# cslr_aif register map
Vendor: Texas Instruments
Registers are 32-bit, access per field, reset 0x0 unless marked. A register's access mark holds for its fields unless they carry their own. Offsets are as the file gives them; [hi:lo] are bit positions; {n}, {i} and the like mark numbered series; 'fields as' and 'values as' point back to an identical list.

## AIF (part 4 of 5) — High-speed interface for BTS antenna data
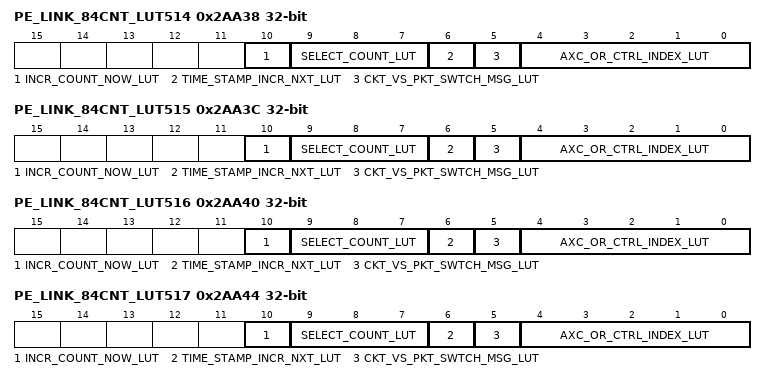
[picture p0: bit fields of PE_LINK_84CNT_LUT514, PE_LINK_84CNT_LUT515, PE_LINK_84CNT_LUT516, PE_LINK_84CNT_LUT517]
0x2AA38 PE_LINK_84CNT_LUT514 — Protocol Encoder Link 84 Count LUT{PE_LINK_84CNT_LUT5}
  [10] INCR_COUNT_NOW_LUT rw — controls counter to increment, Incremented value is used for next operation (current operation uses current counter value)
    1=ICNR; 0=NO_INCR
  [9:7] SELECT_COUNT_LUT rw — Bits [2:0]: "0"-"3": Selects 4x Control Slot Counters or "4": 1x Data Slot Counter for Increment and for use with transmission rule
    {v}=CTRL{v} (v=0..3); 4=DATA
  [6] TIME_STAMP_INCR_NXT_LUT rw — Controls Time Stamp to increment, Incremented value is used for next message
  [5] CKT_VS_PKT_SWTCH_MSG_LUT rw — 0: circuit switched data
    0=PACKET; 1=CIRCUIT
  [4:0] AXC_OR_CTRL_INDEX_LUT rw — Bits [4:0]: Index for accessing the identity LUT.
0x2AA3C PE_LINK_84CNT_LUT515 — Protocol Encoder Link 84 Count LUT{PE_LINK_84CNT_LUT5}
  fields as PE_LINK_84CNT_LUT514
0x2AA40 PE_LINK_84CNT_LUT516 — Protocol Encoder Link 84 Count LUT{PE_LINK_84CNT_LUT5}
  fields as PE_LINK_84CNT_LUT514
0x2AA44 PE_LINK_84CNT_LUT517 — Protocol Encoder Link 84 Count LUT{PE_LINK_84CNT_LUT5}
  fields as PE_LINK_84CNT_LUT514
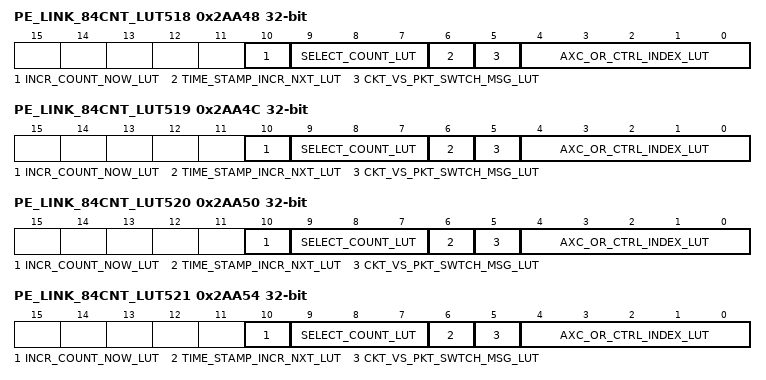
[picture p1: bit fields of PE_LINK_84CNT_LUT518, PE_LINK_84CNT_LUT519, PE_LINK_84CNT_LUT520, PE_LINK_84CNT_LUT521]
0x2AA48 PE_LINK_84CNT_LUT518 — Protocol Encoder Link 84 Count LUT{PE_LINK_84CNT_LUT5}
  fields as PE_LINK_84CNT_LUT514
0x2AA4C PE_LINK_84CNT_LUT519 — Protocol Encoder Link 84 Count LUT{PE_LINK_84CNT_LUT5}
  fields as PE_LINK_84CNT_LUT514
0x2AA50 PE_LINK_84CNT_LUT520 — Protocol Encoder Link 84 Count LUT{PE_LINK_84CNT_LUT5}
  fields as PE_LINK_84CNT_LUT514
0x2AA54 PE_LINK_84CNT_LUT521 — Protocol Encoder Link 84 Count LUT{PE_LINK_84CNT_LUT5}
  fields as PE_LINK_84CNT_LUT514
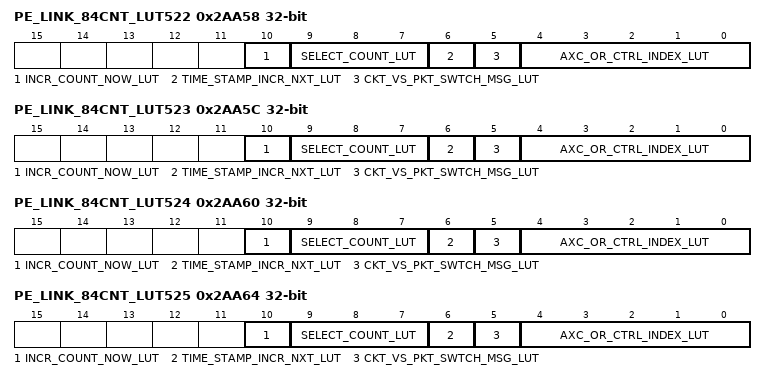
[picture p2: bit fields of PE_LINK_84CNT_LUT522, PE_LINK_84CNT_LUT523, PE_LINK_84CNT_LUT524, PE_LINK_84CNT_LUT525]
0x2AA58 PE_LINK_84CNT_LUT522 — Protocol Encoder Link 84 Count LUT{PE_LINK_84CNT_LUT5}
  fields as PE_LINK_84CNT_LUT514
0x2AA5C PE_LINK_84CNT_LUT523 — Protocol Encoder Link 84 Count LUT{PE_LINK_84CNT_LUT5}
  fields as PE_LINK_84CNT_LUT514
0x2AA60 PE_LINK_84CNT_LUT524 — Protocol Encoder Link 84 Count LUT{PE_LINK_84CNT_LUT5}
  fields as PE_LINK_84CNT_LUT514
0x2AA64 PE_LINK_84CNT_LUT525 — Protocol Encoder Link 84 Count LUT{PE_LINK_84CNT_LUT5}
  fields as PE_LINK_84CNT_LUT514
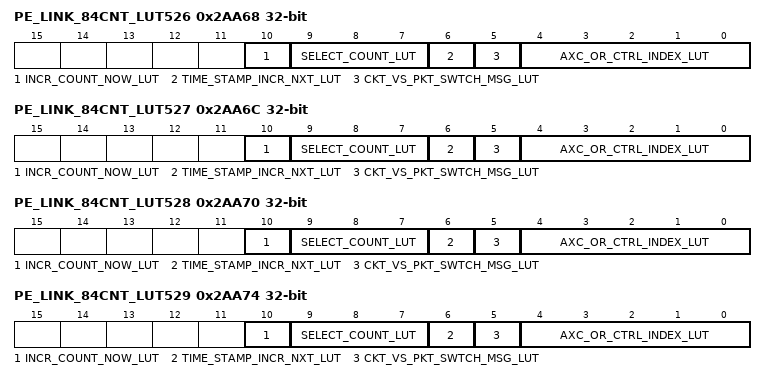
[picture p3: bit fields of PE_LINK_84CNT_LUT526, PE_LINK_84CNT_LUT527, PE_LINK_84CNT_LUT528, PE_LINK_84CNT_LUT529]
0x2AA68 PE_LINK_84CNT_LUT526 — Protocol Encoder Link 84 Count LUT{PE_LINK_84CNT_LUT5}
  fields as PE_LINK_84CNT_LUT514
0x2AA6C PE_LINK_84CNT_LUT527 — Protocol Encoder Link 84 Count LUT{PE_LINK_84CNT_LUT5}
  fields as PE_LINK_84CNT_LUT514
0x2AA70 PE_LINK_84CNT_LUT528 — Protocol Encoder Link 84 Count LUT{PE_LINK_84CNT_LUT5}
  fields as PE_LINK_84CNT_LUT514
0x2AA74 PE_LINK_84CNT_LUT529 — Protocol Encoder Link 84 Count LUT{PE_LINK_84CNT_LUT5}
  fields as PE_LINK_84CNT_LUT514
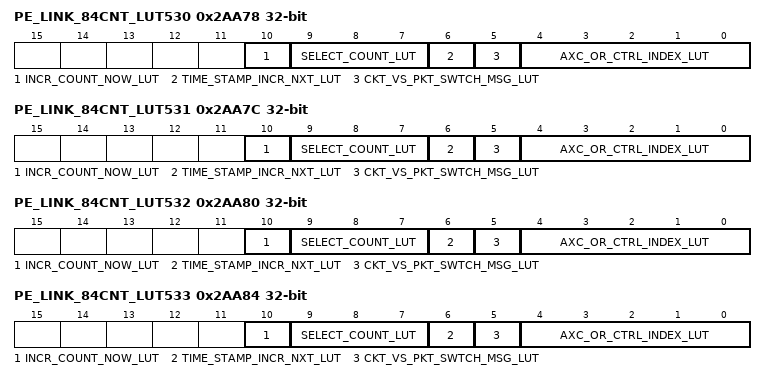
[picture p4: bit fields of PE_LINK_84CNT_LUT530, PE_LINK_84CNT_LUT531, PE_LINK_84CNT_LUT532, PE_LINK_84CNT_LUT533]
0x2AA78 PE_LINK_84CNT_LUT530 — Protocol Encoder Link 84 Count LUT{PE_LINK_84CNT_LUT5}
  fields as PE_LINK_84CNT_LUT514
0x2AA7C PE_LINK_84CNT_LUT531 — Protocol Encoder Link 84 Count LUT{PE_LINK_84CNT_LUT5}
  fields as PE_LINK_84CNT_LUT514
0x2AA80 PE_LINK_84CNT_LUT532 — Protocol Encoder Link 84 Count LUT{PE_LINK_84CNT_LUT5}
  fields as PE_LINK_84CNT_LUT514
0x2AA84 PE_LINK_84CNT_LUT533 — Protocol Encoder Link 84 Count LUT{PE_LINK_84CNT_LUT5}
  fields as PE_LINK_84CNT_LUT514
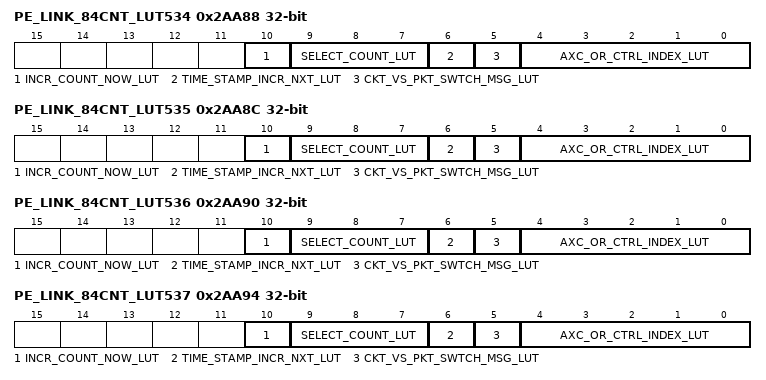
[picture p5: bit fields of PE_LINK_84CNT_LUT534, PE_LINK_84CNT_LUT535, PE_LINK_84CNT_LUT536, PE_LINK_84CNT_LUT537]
0x2AA88 PE_LINK_84CNT_LUT534 — Protocol Encoder Link 84 Count LUT{PE_LINK_84CNT_LUT5}
  fields as PE_LINK_84CNT_LUT514
0x2AA8C PE_LINK_84CNT_LUT535 — Protocol Encoder Link 84 Count LUT{PE_LINK_84CNT_LUT5}
  fields as PE_LINK_84CNT_LUT514
0x2AA90 PE_LINK_84CNT_LUT536 — Protocol Encoder Link 84 Count LUT{PE_LINK_84CNT_LUT5}
  fields as PE_LINK_84CNT_LUT514
0x2AA94 PE_LINK_84CNT_LUT537 — Protocol Encoder Link 84 Count LUT{PE_LINK_84CNT_LUT5}
  fields as PE_LINK_84CNT_LUT514
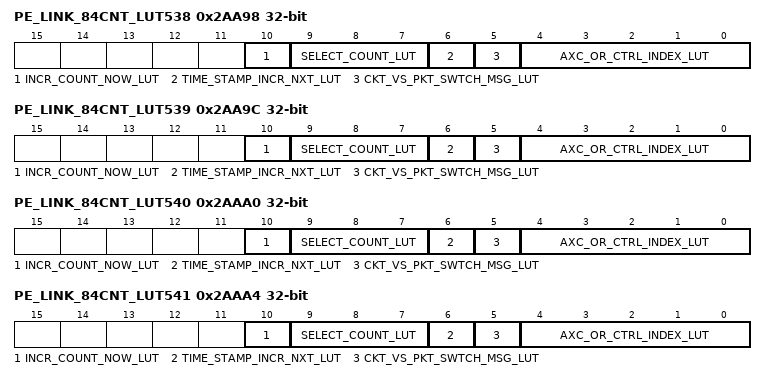
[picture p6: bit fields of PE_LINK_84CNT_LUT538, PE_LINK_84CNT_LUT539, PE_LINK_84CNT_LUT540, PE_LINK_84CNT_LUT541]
0x2AA98 PE_LINK_84CNT_LUT538 — Protocol Encoder Link 84 Count LUT{PE_LINK_84CNT_LUT5}
  fields as PE_LINK_84CNT_LUT514
0x2AA9C PE_LINK_84CNT_LUT539 — Protocol Encoder Link 84 Count LUT{PE_LINK_84CNT_LUT5}
  fields as PE_LINK_84CNT_LUT514
0x2AAA0 PE_LINK_84CNT_LUT540 — Protocol Encoder Link 84 Count LUT{PE_LINK_84CNT_LUT5}
  fields as PE_LINK_84CNT_LUT514
0x2AAA4 PE_LINK_84CNT_LUT541 — Protocol Encoder Link 84 Count LUT{PE_LINK_84CNT_LUT5}
  fields as PE_LINK_84CNT_LUT514
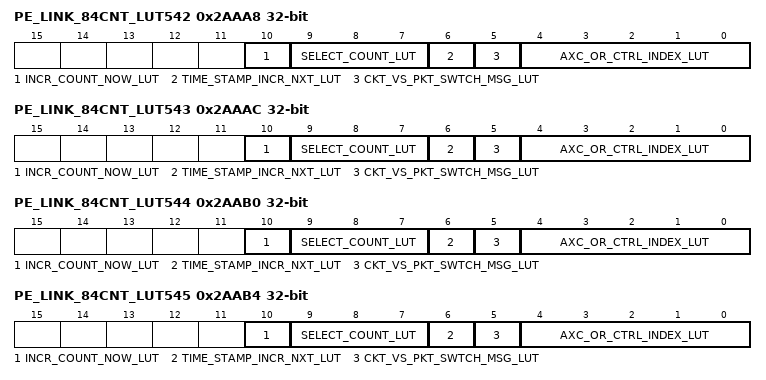
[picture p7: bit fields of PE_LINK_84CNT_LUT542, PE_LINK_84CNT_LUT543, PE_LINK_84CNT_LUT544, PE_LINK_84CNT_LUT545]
0x2AAA8 PE_LINK_84CNT_LUT542 — Protocol Encoder Link 84 Count LUT{PE_LINK_84CNT_LUT5}
  fields as PE_LINK_84CNT_LUT514
0x2AAAC PE_LINK_84CNT_LUT543 — Protocol Encoder Link 84 Count LUT{PE_LINK_84CNT_LUT5}
  fields as PE_LINK_84CNT_LUT514
0x2AAB0 PE_LINK_84CNT_LUT544 — Protocol Encoder Link 84 Count LUT{PE_LINK_84CNT_LUT5}
  fields as PE_LINK_84CNT_LUT514
0x2AAB4 PE_LINK_84CNT_LUT545 — Protocol Encoder Link 84 Count LUT{PE_LINK_84CNT_LUT5}
  fields as PE_LINK_84CNT_LUT514
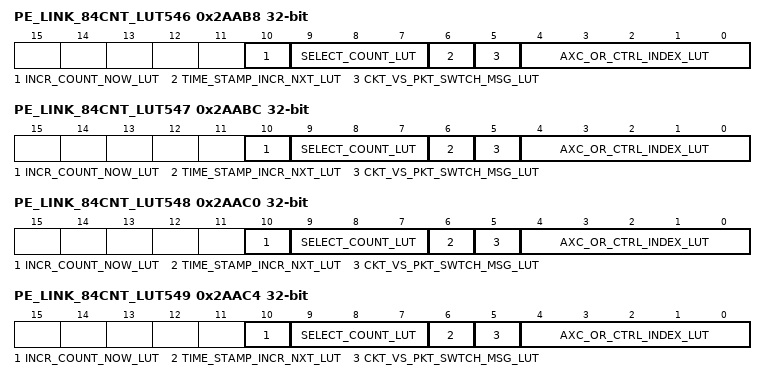
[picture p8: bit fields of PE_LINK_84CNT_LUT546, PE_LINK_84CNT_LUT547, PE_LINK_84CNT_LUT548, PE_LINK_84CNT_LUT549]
0x2AAB8 PE_LINK_84CNT_LUT546 — Protocol Encoder Link 84 Count LUT{PE_LINK_84CNT_LUT5}
  fields as PE_LINK_84CNT_LUT514
0x2AABC PE_LINK_84CNT_LUT547 — Protocol Encoder Link 84 Count LUT{PE_LINK_84CNT_LUT5}
  fields as PE_LINK_84CNT_LUT514
0x2AAC0 PE_LINK_84CNT_LUT548 — Protocol Encoder Link 84 Count LUT{PE_LINK_84CNT_LUT5}
  fields as PE_LINK_84CNT_LUT514
0x2AAC4 PE_LINK_84CNT_LUT549 — Protocol Encoder Link 84 Count LUT{PE_LINK_84CNT_LUT5}
  fields as PE_LINK_84CNT_LUT514
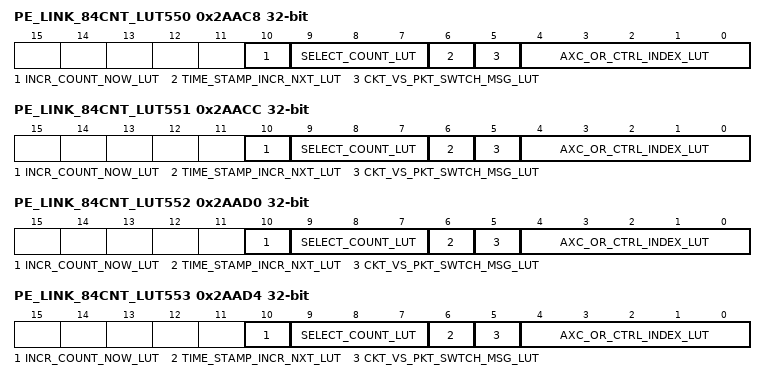
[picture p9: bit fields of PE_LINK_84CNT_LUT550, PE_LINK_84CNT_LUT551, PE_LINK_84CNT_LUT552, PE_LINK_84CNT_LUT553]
0x2AAC8 PE_LINK_84CNT_LUT550 — Protocol Encoder Link 84 Count LUT{PE_LINK_84CNT_LUT5}
  fields as PE_LINK_84CNT_LUT514
0x2AACC PE_LINK_84CNT_LUT551 — Protocol Encoder Link 84 Count LUT{PE_LINK_84CNT_LUT5}
  fields as PE_LINK_84CNT_LUT514
0x2AAD0 PE_LINK_84CNT_LUT552 — Protocol Encoder Link 84 Count LUT{PE_LINK_84CNT_LUT5}
  fields as PE_LINK_84CNT_LUT514
0x2AAD4 PE_LINK_84CNT_LUT553 — Protocol Encoder Link 84 Count LUT{PE_LINK_84CNT_LUT5}
  fields as PE_LINK_84CNT_LUT514
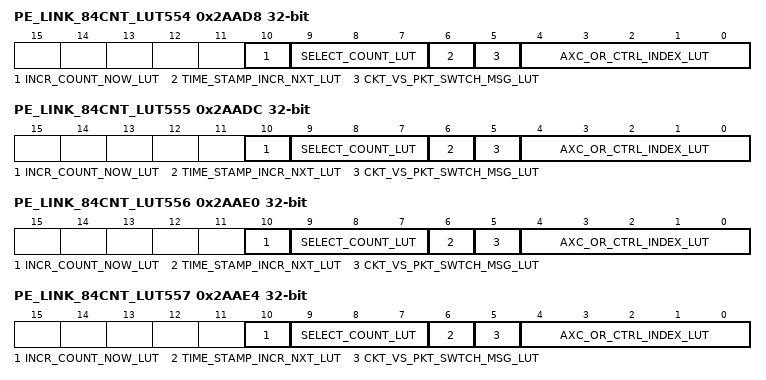
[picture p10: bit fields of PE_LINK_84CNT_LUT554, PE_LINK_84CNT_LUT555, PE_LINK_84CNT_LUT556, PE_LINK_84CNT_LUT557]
0x2AAD8 PE_LINK_84CNT_LUT554 — Protocol Encoder Link 84 Count LUT{PE_LINK_84CNT_LUT5}
  fields as PE_LINK_84CNT_LUT514
0x2AADC PE_LINK_84CNT_LUT555 — Protocol Encoder Link 84 Count LUT{PE_LINK_84CNT_LUT5}
  fields as PE_LINK_84CNT_LUT514
0x2AAE0 PE_LINK_84CNT_LUT556 — Protocol Encoder Link 84 Count LUT{PE_LINK_84CNT_LUT5}
  fields as PE_LINK_84CNT_LUT514
0x2AAE4 PE_LINK_84CNT_LUT557 — Protocol Encoder Link 84 Count LUT{PE_LINK_84CNT_LUT5}
  fields as PE_LINK_84CNT_LUT514
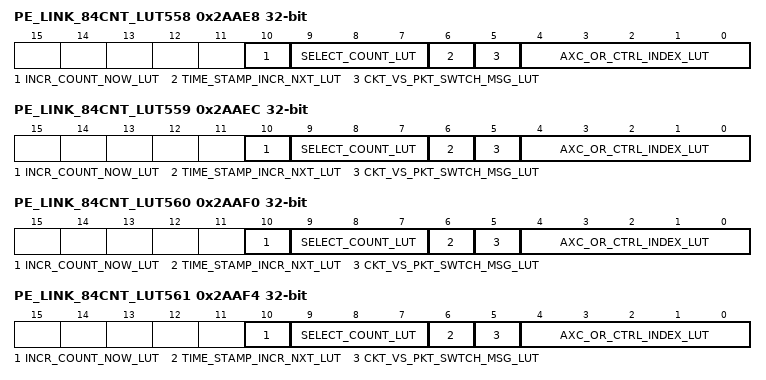
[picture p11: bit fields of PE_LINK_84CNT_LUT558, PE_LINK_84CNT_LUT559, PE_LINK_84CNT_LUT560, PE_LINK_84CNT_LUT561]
0x2AAE8 PE_LINK_84CNT_LUT558 — Protocol Encoder Link 84 Count LUT{PE_LINK_84CNT_LUT5}
  fields as PE_LINK_84CNT_LUT514
0x2AAEC PE_LINK_84CNT_LUT559 — Protocol Encoder Link 84 Count LUT{PE_LINK_84CNT_LUT5}
  fields as PE_LINK_84CNT_LUT514
0x2AAF0 PE_LINK_84CNT_LUT560 — Protocol Encoder Link 84 Count LUT{PE_LINK_84CNT_LUT5}
  fields as PE_LINK_84CNT_LUT514
0x2AAF4 PE_LINK_84CNT_LUT561 — Protocol Encoder Link 84 Count LUT{PE_LINK_84CNT_LUT5}
  fields as PE_LINK_84CNT_LUT514
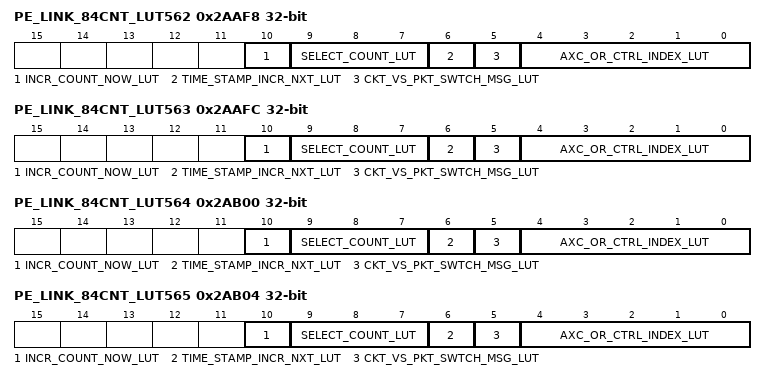
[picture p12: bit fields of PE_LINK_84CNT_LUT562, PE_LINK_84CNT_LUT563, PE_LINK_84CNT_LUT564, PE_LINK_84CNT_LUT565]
0x2AAF8 PE_LINK_84CNT_LUT562 — Protocol Encoder Link 84 Count LUT{PE_LINK_84CNT_LUT5}
  fields as PE_LINK_84CNT_LUT514
0x2AAFC PE_LINK_84CNT_LUT563 — Protocol Encoder Link 84 Count LUT{PE_LINK_84CNT_LUT5}
  fields as PE_LINK_84CNT_LUT514
0x2AB00 PE_LINK_84CNT_LUT564 — Protocol Encoder Link 84 Count LUT{PE_LINK_84CNT_LUT5}
  fields as PE_LINK_84CNT_LUT514
0x2AB04 PE_LINK_84CNT_LUT565 — Protocol Encoder Link 84 Count LUT{PE_LINK_84CNT_LUT5}
  fields as PE_LINK_84CNT_LUT514
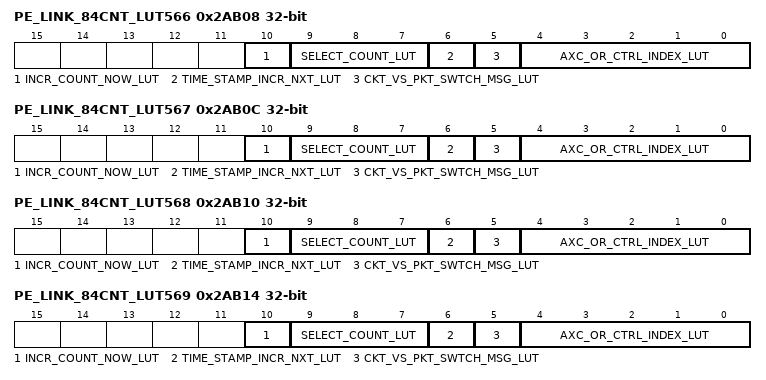
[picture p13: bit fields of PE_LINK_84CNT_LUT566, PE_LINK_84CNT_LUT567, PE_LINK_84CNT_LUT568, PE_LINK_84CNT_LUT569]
0x2AB08 PE_LINK_84CNT_LUT566 — Protocol Encoder Link 84 Count LUT{PE_LINK_84CNT_LUT5}
  fields as PE_LINK_84CNT_LUT514
0x2AB0C PE_LINK_84CNT_LUT567 — Protocol Encoder Link 84 Count LUT{PE_LINK_84CNT_LUT5}
  fields as PE_LINK_84CNT_LUT514
0x2AB10 PE_LINK_84CNT_LUT568 — Protocol Encoder Link 84 Count LUT{PE_LINK_84CNT_LUT5}
  fields as PE_LINK_84CNT_LUT514
0x2AB14 PE_LINK_84CNT_LUT569 — Protocol Encoder Link 84 Count LUT{PE_LINK_84CNT_LUT5}
  fields as PE_LINK_84CNT_LUT514
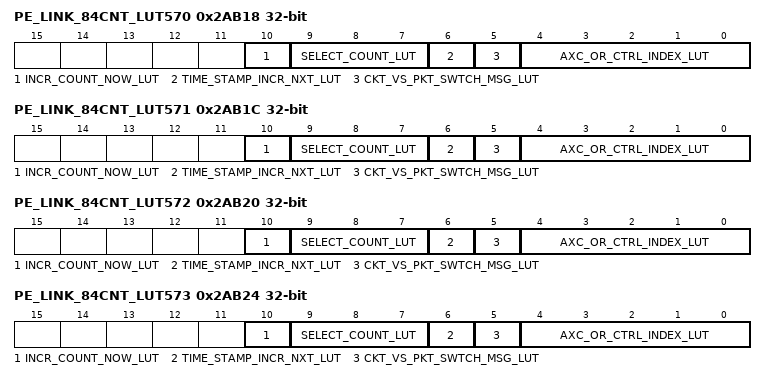
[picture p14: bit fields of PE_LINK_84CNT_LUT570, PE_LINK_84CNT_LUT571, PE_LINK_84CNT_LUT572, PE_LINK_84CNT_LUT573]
0x2AB18 PE_LINK_84CNT_LUT570 — Protocol Encoder Link 84 Count LUT{PE_LINK_84CNT_LUT5}
  fields as PE_LINK_84CNT_LUT514
0x2AB1C PE_LINK_84CNT_LUT571 — Protocol Encoder Link 84 Count LUT{PE_LINK_84CNT_LUT5}
  fields as PE_LINK_84CNT_LUT514
0x2AB20 PE_LINK_84CNT_LUT572 — Protocol Encoder Link 84 Count LUT{PE_LINK_84CNT_LUT5}
  fields as PE_LINK_84CNT_LUT514
0x2AB24 PE_LINK_84CNT_LUT573 — Protocol Encoder Link 84 Count LUT{PE_LINK_84CNT_LUT5}
  fields as PE_LINK_84CNT_LUT514
0x2AB28 PE_LINK_84CNT_LUT574 — Protocol Encoder Link 84 Count LUT{PE_LINK_84CNT_LUT5}
  fields as PE_LINK_84CNT_LUT514
0x2AB2C PE_LINK_84CNT_LUT575 — Protocol Encoder Link 84 Count LUT{PE_LINK_84CNT_LUT5}
  fields as PE_LINK_84CNT_LUT514
0x2AB30 PE_LINK_84CNT_LUT576 — Protocol Encoder Link 84 Count LUT{PE_LINK_84CNT_LUT5}
  fields as PE_LINK_84CNT_LUT514
0x2AB34 PE_LINK_84CNT_LUT577 — Protocol Encoder Link 84 Count LUT{PE_LINK_84CNT_LUT5}
  fields as PE_LINK_84CNT_LUT514
0x2AB38 PE_LINK_84CNT_LUT578 — Protocol Encoder Link 84 Count LUT{PE_LINK_84CNT_LUT5}
  fields as PE_LINK_84CNT_LUT514
0x2AB3C PE_LINK_84CNT_LUT579 — Protocol Encoder Link 84 Count LUT{PE_LINK_84CNT_LUT5}
  fields as PE_LINK_84CNT_LUT514
0x2AB40 PE_LINK_84CNT_LUT580 — Protocol Encoder Link 84 Count LUT{PE_LINK_84CNT_LUT5}
  fields as PE_LINK_84CNT_LUT514
0x2AB44 PE_LINK_84CNT_LUT581 — Protocol Encoder Link 84 Count LUT{PE_LINK_84CNT_LUT5}
  fields as PE_LINK_84CNT_LUT514
0x2AB48 PE_LINK_84CNT_LUT582 — Protocol Encoder Link 84 Count LUT{PE_LINK_84CNT_LUT5}
  fields as PE_LINK_84CNT_LUT514
0x2AB4C PE_LINK_84CNT_LUT583 — Protocol Encoder Link 84 Count LUT{PE_LINK_84CNT_LUT5}
  fields as PE_LINK_84CNT_LUT514
0x2AC00 PE_LINK_ID_LUT05_0 — Protocol Encoder Identity LUT part 0{PE_LINK_ID_LUT05}
  [29:25] OBSAI_TYPE_LUT rw — Bits [4:0]: OBSAI type, fixed per antenna carrier (circuit switched only)
  [24:12] OBSAI_ADR_LUT rw — Bits [12:0]: OBSAI address, fixed per antenna carrier (circuit switched only)
  [11:10] AGGR_CTL_LUT rw — Bits [1:0]: Aggregation control bits (assuming Tx_Rule passes)
    0=NOP (NOP (Ag still pulls from FIFO, but does not use read PE data bytes)); 1=INSERT; 2=ADD15_16 (Add 15/16bit); 3=ADD7_8 (Add 7/8bit)
  [9:8] DATA_FORMAT_LUT rw — Bits [1:0]: Internal Data format:
    0=DL_FMT (DL Format(only legal with burst of 4)); 1=UL_FMT (UL RSA Format(only legal for burst of 8)); 2=PIC_FMT (PIC MAI); 3=GEN_FMT (Generic Format)
  [7:5] OFFSET_ADR_LUT rw — Bits [2:0]: Circularly offsets reads from circuit switched RAM by n*4 chips. 8 chip orientated UL data disregard the LSB assuming it is zero. This offset is used to correct RAM alignment between streams different MOD32 offsets with one another. Allows chained DMA's to be more regular.
  [4:0] FIFO_INDEX_LUT rw — Bite [4:0]: pktsw FIFO Index[4:0]. Used to address fifo corresponding to this link.
0x2AC04 PE_LINK_ID_LUT05_1 — Protocol Encoder Identity LUT part 0{PE_LINK_ID_LUT05}
  fields as PE_LINK_ID_LUT05_0
0x2AC08 PE_LINK_ID_LUT05_2 — Protocol Encoder Identity LUT part 0{PE_LINK_ID_LUT05}
  fields as PE_LINK_ID_LUT05_0
0x2AC0C PE_LINK_ID_LUT05_3 — Protocol Encoder Identity LUT part 0{PE_LINK_ID_LUT05}
  fields as PE_LINK_ID_LUT05_0
0x2AC10 PE_LINK_ID_LUT05_4 — Protocol Encoder Identity LUT part 0{PE_LINK_ID_LUT05}
  fields as PE_LINK_ID_LUT05_0
0x2AC14 PE_LINK_ID_LUT05_5 — Protocol Encoder Identity LUT part 0{PE_LINK_ID_LUT05}
  fields as PE_LINK_ID_LUT05_0
0x2AC18 PE_LINK_ID_LUT05_6 — Protocol Encoder Identity LUT part 0{PE_LINK_ID_LUT05}
  fields as PE_LINK_ID_LUT05_0
0x2AC1C PE_LINK_ID_LUT05_7 — Protocol Encoder Identity LUT part 0{PE_LINK_ID_LUT05}
  fields as PE_LINK_ID_LUT05_0
0x2AC20 PE_LINK_ID_LUT05_8 — Protocol Encoder Identity LUT part 0{PE_LINK_ID_LUT05}
  fields as PE_LINK_ID_LUT05_0
0x2AC24 PE_LINK_ID_LUT05_9 — Protocol Encoder Identity LUT part 0{PE_LINK_ID_LUT05}
  fields as PE_LINK_ID_LUT05_0
0x2AC28 PE_LINK_ID_LUT05_10 — Protocol Encoder Identity LUT part 0{PE_LINK_ID_LUT05}
  fields as PE_LINK_ID_LUT05_0
0x2AC2C PE_LINK_ID_LUT05_11 — Protocol Encoder Identity LUT part 0{PE_LINK_ID_LUT05}
  fields as PE_LINK_ID_LUT05_0
0x2AC30 PE_LINK_ID_LUT05_12 — Protocol Encoder Identity LUT part 0{PE_LINK_ID_LUT05}
  fields as PE_LINK_ID_LUT05_0
0x2AC34 PE_LINK_ID_LUT05_13 — Protocol Encoder Identity LUT part 0{PE_LINK_ID_LUT05}
  fields as PE_LINK_ID_LUT05_0
0x2AC38 PE_LINK_ID_LUT05_14 — Protocol Encoder Identity LUT part 0{PE_LINK_ID_LUT05}
  fields as PE_LINK_ID_LUT05_0
0x2AC3C PE_LINK_ID_LUT05_15 — Protocol Encoder Identity LUT part 0{PE_LINK_ID_LUT05}
  fields as PE_LINK_ID_LUT05_0
0x2AC40 PE_LINK_ID_LUT05_16 — Protocol Encoder Identity LUT part 0{PE_LINK_ID_LUT05}
  fields as PE_LINK_ID_LUT05_0
0x2AC44 PE_LINK_ID_LUT05_17 — Protocol Encoder Identity LUT part 0{PE_LINK_ID_LUT05}
  fields as PE_LINK_ID_LUT05_0
0x2AC48 PE_LINK_ID_LUT05_18 — Protocol Encoder Identity LUT part 0{PE_LINK_ID_LUT05}
  fields as PE_LINK_ID_LUT05_0
0x2AC4C PE_LINK_ID_LUT05_19 — Protocol Encoder Identity LUT part 0{PE_LINK_ID_LUT05}
  fields as PE_LINK_ID_LUT05_0
0x2AC50 PE_LINK_ID_LUT05_20 — Protocol Encoder Identity LUT part 0{PE_LINK_ID_LUT05}
  fields as PE_LINK_ID_LUT05_0
0x2AD00 PE_LINK_ID_LUT15_0 — Protocol Encoder Identity LUT part 1{PE_LINK_ID_LUT15}
  [21:11] TX_RULE_MCOMPARE_LUT rw — Bits [10:0]: Transmission rule compare bits. Field is bitwise XNOR with current counter value. Enabled results (see tx_rule_mask) are reduction AND giving a pass/fail of the transmission rule.
  [10:0] TX_RULE_MASK_LUT rw — Bits [10:0]: transmission rule mask. Indicates which counter bits should be compared. 0: indicates bit automatically passes compare 1: indicates counter bit should be compared with tx_rule_compare field.
0x2AD04 PE_LINK_ID_LUT15_1 — Protocol Encoder Identity LUT part 1{PE_LINK_ID_LUT15}
  fields as PE_LINK_ID_LUT15_0
0x2AD08 PE_LINK_ID_LUT15_2 — Protocol Encoder Identity LUT part 1{PE_LINK_ID_LUT15}
  fields as PE_LINK_ID_LUT15_0
0x2AD0C PE_LINK_ID_LUT15_3 — Protocol Encoder Identity LUT part 1{PE_LINK_ID_LUT15}
  fields as PE_LINK_ID_LUT15_0
0x2AD10 PE_LINK_ID_LUT15_4 — Protocol Encoder Identity LUT part 1{PE_LINK_ID_LUT15}
  fields as PE_LINK_ID_LUT15_0
0x2AD14 PE_LINK_ID_LUT15_5 — Protocol Encoder Identity LUT part 1{PE_LINK_ID_LUT15}
  fields as PE_LINK_ID_LUT15_0
0x2AD18 PE_LINK_ID_LUT15_6 — Protocol Encoder Identity LUT part 1{PE_LINK_ID_LUT15}
  fields as PE_LINK_ID_LUT15_0
0x2AD1C PE_LINK_ID_LUT15_7 — Protocol Encoder Identity LUT part 1{PE_LINK_ID_LUT15}
  fields as PE_LINK_ID_LUT15_0
0x2AD20 PE_LINK_ID_LUT15_8 — Protocol Encoder Identity LUT part 1{PE_LINK_ID_LUT15}
  fields as PE_LINK_ID_LUT15_0
0x2AD24 PE_LINK_ID_LUT15_9 — Protocol Encoder Identity LUT part 1{PE_LINK_ID_LUT15}
  fields as PE_LINK_ID_LUT15_0
0x2AD28 PE_LINK_ID_LUT15_10 — Protocol Encoder Identity LUT part 1{PE_LINK_ID_LUT15}
  fields as PE_LINK_ID_LUT15_0
0x2AD2C PE_LINK_ID_LUT15_11 — Protocol Encoder Identity LUT part 1{PE_LINK_ID_LUT15}
  fields as PE_LINK_ID_LUT15_0
0x2AD30 PE_LINK_ID_LUT15_12 — Protocol Encoder Identity LUT part 1{PE_LINK_ID_LUT15}
  fields as PE_LINK_ID_LUT15_0
0x2AD34 PE_LINK_ID_LUT15_13 — Protocol Encoder Identity LUT part 1{PE_LINK_ID_LUT15}
  fields as PE_LINK_ID_LUT15_0
0x2AD38 PE_LINK_ID_LUT15_14 — Protocol Encoder Identity LUT part 1{PE_LINK_ID_LUT15}
  fields as PE_LINK_ID_LUT15_0
0x2AD3C PE_LINK_ID_LUT15_15 — Protocol Encoder Identity LUT part 1{PE_LINK_ID_LUT15}
  fields as PE_LINK_ID_LUT15_0
0x2AD40 PE_LINK_ID_LUT15_16 — Protocol Encoder Identity LUT part 1{PE_LINK_ID_LUT15}
  fields as PE_LINK_ID_LUT15_0
0x2AD44 PE_LINK_ID_LUT15_17 — Protocol Encoder Identity LUT part 1{PE_LINK_ID_LUT15}
  fields as PE_LINK_ID_LUT15_0
0x2AD48 PE_LINK_ID_LUT15_18 — Protocol Encoder Identity LUT part 1{PE_LINK_ID_LUT15}
  fields as PE_LINK_ID_LUT15_0
0x2AD4C PE_LINK_ID_LUT15_19 — Protocol Encoder Identity LUT part 1{PE_LINK_ID_LUT15}
  fields as PE_LINK_ID_LUT15_0
0x2AD50 PE_LINK_ID_LUT15_20 — Protocol Encoder Identity LUT part 1{PE_LINK_ID_LUT15}
  fields as PE_LINK_ID_LUT15_0
0x2B000 PE_CFG — Protocol Encoder Configuration Register
  [n+16] LINK_BURST_8VS4_{n} rw (n=0..5) — Bits [5:0]: Bit mapped per link
    0=DL; 1=UL
  [n+8] LINK_ENABLE_{n} rw (n=0..5) — Bits [5:0]: Bit mapped per link
    0=DISABLED; 1=ENABLED
  [n] PE_CPRI_CNTL_EN_{n} rw (n=0..5) — 1'b1: CPRI words are read from RAM and constructed
    0=DISABLED; 1=ENABLED
0x30000 EE_LINK0_IRS_A — Event Enable Link Interrupt Source Raw Status Register A
  [28] PD_CPRI_HFN_ERR rw — CPRI hyper frame number different than FSM expected
  [27] PD_OBSAI_TYPE_ERR rw — OBSAI header type look up resulted in illegal type
  [26] PD_OBSAI_ADR_ERR rw — OBSAI header address look up resulted in illegal address
  [25] PD_FSYNC_OR_K_ERR rw — Frame sync or K character different than FSM expected
  [24] PD_TIME_STAMP_ERR rw — OBSAI time stamp error
  [16] SD_LOS rw — Loss of signal condition
  [15] RM_LOF_STATE rw — CPRI receiver entered State 0 or State 1
  [14] RM_HFNSYNC_STATE rw — CPRI receiver in FSM State 3
  [13] RM_RCVD_LOF rw — Received lof (Z.130.0, b4) (CPRI only)
  [12] RM_RCVD_LOS rw — Received los (Z.130.0, b3) (CPRI only)
  [11] RM_RCVD_SDI rw — Received sdi (Z.130.0, b2) (CPRI only)
  [10] RM_RCVD_RAI rw — Received rai (Z.130.0, b1) (CPRI only)
  [9] RM_RCVD_RST rw — Received reset (Z.130.0, b0) (CPRI only)
  [8] RM_K30P7_DET rw — Indicates that a K30.7 character was received (OBSAI only).
  [7] RM_MSTR_FRAME_BNDY_OUT_OF_RANGE rw — This error is indicated when received Master Frame is detected outside the programmable window valid_mstr_frame_wind (typically 65ns)
  [6] RM_MISSING_FRAME_INDICATOR rw — Indicates that a K28.7 (OBSAI) or a K28.5 (CPRI) character was missing and assumes receiver is in state ST3
  [5] RM_MISSING_K28P5 rw — Indicates that a K28.5 characters was missing (OBSAI only and assumes receiver is in frame sync state ST3.
  [4] RM_BLOCK_BNDRY_DET rw — Block boundary (OBSAI) is detected or at a Hyperframe boundary (CPRI)
  [3] RM_FRAME_BNDRY_DET rw — Master frame boundary (OBSAI) is detected or at a Hyperframe boundary (CPRI) that delimits a UMTS frame
  [2] RM_8B10B_DECODE_ERROR rw — 8b10b error has occurred.
  [1] RM_LOS_DET rw — los_thold is reached
  [0] RM_SYNC_STATUS_CHANGE rw — Indicates the status of the rx state machine.
0x30004 EE_LINK0_IRS_B — Event Enable Link Interrupt Source Raw Status Register B
  [20] DB_CIRSW_OUT_DMA_UFLOW rw — Circuit Switch RAM Outbound DMA underflow
  [19] DB_CIRSW_IN_DMA_UFLOW rw — Circuit Switch RAM Inbound DMA underflow
  [18] DB_CIRSW_OUT_BURST_OFLOW rw — Circuit Switch RAM Outbound RAM burst strobe overflow
  [17] DB_CIRSW_OUT_DMA_OFLOW rw — Circuit Switch RAM Outbound DMA overflow
  [16] DB_CIRSW_IN_DMA_OFLOW rw — Circuit Switch RAM Inbound DMA overflow
  [13] CD_OUT_FIFO_UNF rw — Output FIFO underflow
  [12] CD_OUT_FIFO_OVF rw — Output FIFO overflow
  [10] AG_LINK_SUM_OVF rw — Summation overflow on any AxC
  [9] AG_FRM_ALIGN_ERR rw — Frame alignment error between PE and CD
  [8] AG_LINK_HDR_ERR rw — Link header error on any message slot
  [4] TM_FIFO_UNF rw — TX MAC FIFO Underflow flag
  [3] TM_FIFO_OVF rw — TX MAC FIFO Overflow flag
  [2] TM_DATA_NOT_ALIGNED rw — This error is indicated when data to be transmitted is detected as not aligned with Master Frame + delta_offset (i.e. Frame boundary to be transmitted is not aligned with frame boundary received internally)
  [1] TM_FRAME_NOT_ALIGNED rw — This error is indicated when the frame strobe from the Frame Sync Module is not aligned with Master Frame + delta_offset.
  [0] TM_SYNC_STATUS_CHANGE rw — Indicates a change of tx state machine state
{0x30008+0x800*i} EE_EV0_LINK_IMS_A{i} (i=0..5) — Event 0 Link Interrupt Source Masked Status Reg A
  [28] PD_CPRI_HFN_ERR rw — CPRI hyper frame number different than FSM expected
  [27] PD_OBSAI_TYPE_ERR rw — OBSAI header type look up resulted in illegal type
  [26] PD_OBSAI_ADR_ERR rw — OBSAI header address look up resulted in illegal address
  [25] PD_FSYNC_OR_K_ERR rw — Frame sync or K character different than FSM expected
  [24] PD_TIME_STAMP_ERROR rw — OBSAI time stamp error
  [16] SD_LOS rw — Loss of signal condition
  [15] RM_LOF_STATE rw — CPRI receiver entered State 0 or State 1
  [14] RM_HFNSYNC_STATE rw — CPRI receiver in FSM State 3
  [13] RM_RCVD_LOF rw — Received lof (Z.130.0, b4) (CPRI only)
  [12] RM_RCVD_LOS rw — Received los (Z.130.0, b3) (CPRI only)
  [11] RM_RCVD_SDI rw — Received sdi (Z.130.0, b2) (CPRI only)
  [10] RM_RCVD_RAI rw — Received rai (Z.130.0, b1) (CPRI only)
  [9] RM_RCVD_RST rw — Received reset (Z.130.0, b0) (CPRI only)
  [8] RM_K30P7_DET rw — Indicates that a K30.7 character was detected (OBSAI only).
  [7] RM_MSTR_FRAME_BNDY_OUT_OF_RANGE rw — This error is indicated when received Master Frame is detected outside the programmable window valid_mstr_frame_wind (typically 65ns)
  [6] RM_MISSING_FRAME_INDICATOR rw — Indicates that a K28.7 (OBSAI) or a K28.5 (CPRI) character was missing and assumes receiver is in state ST3
  [5] RM_MISSING_K28p5 rw — Indicates that a K28.5 characters was missing (OBSAI only and assumes receiver is in frame sync state ST3.
  [4] RM_BLOCK_BNDRY_DET rw — Block boundary (OBSAI) is detected or at a Hyperframe boundary (CPRI)
  [3] RM_FRAME_BNDRY_DET rw — Master frame boundary (OBSAI) is detected or at a Hyperframe boundary (CPRI) that delimits a UMTS frame
  [2] RM_8B10B_DECODE_ERROR rw — 8b10b error has occurred.
  [1] RM_LOS_DET rw — los_thold is reached
  [0] RM_SYNC_STATUS_CHANGE rw — Indicates the status of the rx state machine.
{0x3000C+0x800*i} EE_EV0_LINK_IMS_B{i} (i=0..5) — Event 0 Link Interrupt Source Masked Status Reg B
  fields as EE_LINK0_IRS_B
{0x30010+0x800*i} EE_EV1_LINK_IMS_A{i} (i=0..5) — Event 1 Link Interrupt Source Masked Status Reg A
  fields as EE_EV0_LINK_IMS_A0
{0x30014+0x800*i} EE_EV1_LINK_IMS_B{i} (i=0..5) — Event 1 Link Interrupt Source Masked Status Reg B
  fields as EE_LINK0_IRS_B
{0x30018+0x800*i} EE_EV0_LINK_MSK_SET_A{i} (i=0..5) — Event 0 Link Interrupt Source Mask Set Reg A
  [28] PD_CPRI_HFN_ERR_MSK rw — Mask for associated bit in the EE_EV0_LINK_ISM_A register. Writing this bit to a 1 sets the mask to 1 to enable the associated error/alarm. Reading this register returns the value of the mask bit.
  [27] PD_OBSAI_TYPE_ERR_MSK rw — Mask for associated bit in the EE_EV0_LINK_ISM_A register. Writing this bit to a 1 sets the mask to 1 to enable the associated error/alarm. Reading this register returns the value of the mask bit.
  [26] PD_OBSAI_ADR_ERR_MSK rw — Mask for associated bit in the EE_EV0_LINK_ISM_A register. Writing this bit to a 1 sets the mask to 1 to enable the associated error/alarm. Reading this register returns the value of the mask bit.
  [25] PD_FSYNC_OR_K_ERR_MSK rw — Mask for associated bit in the EE_EV0_LINK_ISM_A register. Writing this bit to a 1 sets the mask to 1 to enable the associated error/alarm. Reading this register returns the value of the mask bit.
  [24] PD_TIME_STAMP_ERR_MSK rw — Mask for associated bit in the EE_EV0_LINK_ISM_A register. Writing this bit to a 1 sets the mask to 1 to enable the associated error/alarm. Reading this register returns the value of the mask bit.
  [16] SD_LOS_MSK rw — Mask for associated bit in the EE_EV0_LINK_ISM_A register. Writing this bit to a 1 sets the mask to 1 to enable the associated error/alarm. Reading this register returns the value of the mask bit.
  [15] RM_LOF_STATE_MSK rw — Mask for associated bit in the EE_EV0_LINK_ISM_A register. Writing this bit to a 1 sets the mask to 1 to enable the associated error/alarm. Reading this register returns the value of the mask bit.
  [14] RM_HFNSYNC_STATE_MSK rw — Mask for associated bit in the EE_EV0_LINK_ISM_A register. Writing this bit to a 1 sets the mask to 1 to enable the associated error/alarm. Reading this register returns the value of the mask bit.
  [13] RM_RCVD_LOF_MSK rw — Mask for associated bit in the EE_EV0_LINK_ISM_A register. Writing this bit to a 1 sets the mask to 1 to enable the associated error/alarm. Reading this register returns the value of the mask bit.
  [12] RM_RCVD_LOS_MSK rw — Mask for associated bit in the EE_EV0_LINK_ISM_A register. Writing this bit to a 1 sets the mask to 1 to enable the associated error/alarm. Reading this register returns the value of the mask bit.
  [11] RM_RCVD_SDI_MSK rw — Mask for associated bit in the EE_EV0_LINK_ISM_A register. Writing this bit to a 1 sets the mask to 1 to enable the associated error/alarm. Reading this register returns the value of the mask bit.
  [10] RM_RCVD_RAI_MSK rw — Mask for associated bit in the EE_EV0_LINK_ISM_A register. Writing this bit to a 1 sets the mask to 1 to enable the associated error/alarm. Reading this register returns the value of the mask bit.
  [9] RM_RCVD_RST_MSK rw — Mask for associated bit in the EE_EV0_LINK_ISM_A register. Writing this bit to a 1 sets the mask to 1 to enable the associated error/alarm. Reading this register returns the value of the mask bit.
  [8] RM_K30P7_DET_MSK rw — Mask for associated bit in the EE_EV0_LINK_ISM_A register. Writing this bit to a 1 sets the mask to 1 to enable the associated error/alarm. Reading this register returns the value of the mask bit.
  [7] RM_MSTR_FRAME_BNDY_OUT_OF_RANGE_MSK rw — Mask for associated bit in the EE_EV0_LINK_ISM_A register. Writing this bit to a 1 sets the mask to 1 to enable the associated error/alarm. Reading this register returns the value of the mask bit.
  [6] RM_MISSING_FRAME_INDICATOR_MSK rw — Mask for associated bit in the EE_EV0_LINK_ISM_A register. Writing this bit to a 1 sets the mask to 1 to enable the associated error/alarm. Reading this register returns the value of the mask bit.
  [5] RM_MISSING_K28P5_MSK rw — Mask for associated bit in the EE_EV0_LINK_ISM_A register. Writing this bit to a 1 sets the mask to 1 to enable the associated error/alarm. Reading this register returns the value of the mask bit.
  [4] RM_BLOCK_BNDRY_DET_MSK rw — Mask for associated bit in the EE_EV0_LINK_ISM_A register. Writing this bit to a 1 sets the mask to 1 to enable the associated error/alarm. Reading this register returns the value of the mask bit.
  [3] RM_FRAME_BNDRY_DET_MSK rw — Mask for associated bit in the EE_EV0_LINK_ISM_A register. Writing this bit to a 1 sets the mask to 1 to enable the associated error/alarm. Reading this register returns the value of the mask bit.
  [2] RM_8B10B_DECODE_ERR0R_MSK rw — Mask for associated bit in the EE_EV0_LINK_ISM_A register. Writing this bit to a 1 sets the mask to 1 to enable the associated error/alarm. Reading this register returns the value of the mask bit.
  [1] RM_LOS_DET_MSK rw — Mask for associated bit in the EE_EV0_LINK_ISM_A register. Writing this bit to a 1 sets the mask to 1 to enable the associated error/alarm. Reading this register returns the value of the mask bit.
  [0] RM_SYNC_STATUS_CHANGE_MSK rw — Mask for associated bit in the EE_EV0_LINK_ISM_A register. Writing this bit to a 1 sets the mask to 1 to enable the associated error/alarm. Reading this register returns the value of the mask bit.
{0x3001C+0x800*i} EE_EV0_LINK_MSK_SET_B{i} (i=0..5) — Event 0 Link Interrupt Source Mask Set Reg B
  [20] DB_CIRSW_OUT_DMA_UFLOW_MSK rw — Mask for associated bit in the EE_EV0_LINK_ISM_A register. Writing this bit to a 1 sets the mask to 1 to enable the associated error/alarm. Reading this register returns the value of the mask bit.
  [19] DB_CIRSW_IN_DMA_UFLOW_MSK rw — Mask for associated bit in the EE_EV0_LINK_ISM_A register. Writing this bit to a 1 sets the mask to 1 to enable the associated error/alarm. Reading this register returns the value of the mask bit.
  [18] DB_CIRSW_OUT_BURST_OFLOW_MSK rw — Mask for associated bit in the EE_EV0_LINK_ISM_A register. Writing this bit to a 1 sets the mask to 1 to enable the associated error/alarm. Reading this register returns the value of the mask bit.
  [17] DB_CIRSW_OUT_DMA_OFLOW_MSK rw — Mask for associated bit in the EE_EV0_LINK_ISM_A register. Writing this bit to a 1 sets the mask to 1 to enable the associated error/alarm. Reading this register returns the value of the mask bit.
  [16] DB_CIRSW_IN_DMA_OFLOW_MSK rw — Mask for associated bit in the EE_EV0_LINK_ISM_A register. Writing this bit to a 1 sets the mask to 1 to enable the associated error/alarm. Reading this register returns the value of the mask bit.
  [13] CD_OUT_FIFO_UNF_MSK rw — Mask for associated bit in the EE_EV0_LINK_ISM_A register. Writing this bit to a 1 sets the mask to 1 to enable the associated error/alarm. Reading this register returns the value of the mask bit.
  [12] CD_OUT_FIFO_OVF_MSK rw — Mask for associated bit in the EE_EV0_LINK_ISM_A register. Writing this bit to a 1 sets the mask to 1 to enable the associated error/alarm. Reading this register returns the value of the mask bit.
  [10] AG_LINK_SUM_OVF_MSK rw — Mask for associated bit in the EE_EV0_LINK_ISM_A register. Writing this bit to a 1 sets the mask to 1 to enable the associated error/alarm. Reading this register returns the value of the mask bit.
  [9] AG_FRM_ALIGN_ERR_MSK rw — Mask for associated bit in the EE_EV0_LINK_ISM_A register. Writing this bit to a 1 sets the mask to 1 to enable the associated error/alarm. Reading this register returns the value of the mask bit.
  [8] AG_LINK_HDR_ERR_MSK rw — Mask for associated bit in the EE_EV0_LINK_ISM_A register. Writing this bit to a 1 sets the mask to 1 to enable the associated error/alarm. Reading this register returns the value of the mask bit.
  [4] TM_FIFO_UNF_MSK rw — Mask for associated bit in the EE_EV0_LINK_ISM_A register. Writing this bit to a 1 sets the mask to 1 to enable the associated error/alarm. Reading this register returns the value of the mask bit.
  [3] TM_FIFO_OVF_MSK rw — Mask for associated bit in the EE_EV0_LINK_ISM_A register. Writing this bit to a 1 sets the mask to 1 to enable the associated error/alarm. Reading this register returns the value of the mask bit.
  [2] TM_DATA_NOT_ALIGNED_MSK rw — Mask for associated bit in the EE_EV0_LINK_ISM_A register. Writing this bit to a 1 sets the mask to 1 to enable the associated error/alarm. Reading this register returns the value of the mask bit.
  [1] TM_FRAME_NOT_ALIGNED_MSK rw — Mask for associated bit in the EE_EV0_LINK_ISM_A register. Writing this bit to a 1 sets the mask to 1 to enable the associated error/alarm. Reading this register returns the value of the mask bit.
  [0] TM_SYNC_STATUS_CHANGE_MSK rw — Mask for associated bit in the EE_EV0_LINK_ISM_A register. Writing this bit to a 1 sets the mask to 1 to enable the associated error/alarm. Reading this register returns the value of the mask bit.
{0x30020+0x800*i} EE_EV1_LINK_MSK_SET_A{i} (i=0..5) — Event 1 Link Interrupt Source Mask Set Reg A
  [28] PD_CPRI_HFN_ERR_MSK rw — Mask for associated bit in the EE_EV1_LINK_ISM_A register. Writing this bit to a 1 sets the mask to 1 to enable the associated error/alarm. Reading this register returns the value of the mask bit.
  [27] PD_OBSAI_TYPE_ERR_MSK rw — Mask for associated bit in the EE_EV1_LINK_ISM_A register. Writing this bit to a 1 sets the mask to 1 to enable the associated error/alarm. Reading this register returns the value of the mask bit.
  [26] PD_OBSAI_ADR_ERR_MSK rw — Mask for associated bit in the EE_EV1_LINK_ISM_A register. Writing this bit to a 1 sets the mask to 1 to enable the associated error/alarm. Reading this register returns the value of the mask bit.
  [25] PD_FSYNC_OR_K_ERR_MSK rw — Mask for associated bit in the EE_EV1_LINK_ISM_A register. Writing this bit to a 1 sets the mask to 1 to enable the associated error/alarm. Reading this register returns the value of the mask bit.
  [24] PD_TIME_STAMP_ERR_MSK rw — Mask for associated bit in the EE_EV1_LINK_ISM_A register. Writing this bit to a 1 sets the mask to 1 to enable the associated error/alarm. Reading this register returns the value of the mask bit.
  [16] SD_LOS_MSK rw — Mask for associated bit in the EE_EV1_LINK_ISM_A register. Writing this bit to a 1 sets the mask to 1 to enable the associated error/alarm. Reading this register returns the value of the mask bit.
  [15] RM_LOF_STATE_MSK rw — Mask for associated bit in the EE_EV1_LINK_ISM_A register. Writing this bit to a 1 sets the mask to 1 to enable the associated error/alarm. Reading this register returns the value of the mask bit.
  [14] RM_HFNSYNC_STATE_MSK rw — Mask for associated bit in the EE_EV1_LINK_ISM_A register. Writing this bit to a 1 sets the mask to 1 to enable the associated error/alarm. Reading this register returns the value of the mask bit.
  [13] RM_RCVD_LOF_MSK rw — Mask for associated bit in the EE_EV1_LINK_ISM_A register. Writing this bit to a 1 sets the mask to 1 to enable the associated error/alarm. Reading this register returns the value of the mask bit.
  [12] RM_RCVD_LOS_MSK rw — Mask for associated bit in the EE_EV1_LINK_ISM_A register. Writing this bit to a 1 sets the mask to 1 to enable the associated error/alarm. Reading this register returns the value of the mask bit.
  [11] RM_RCVD_SDI_MSK rw — Mask for associated bit in the EE_EV1_LINK_ISM_A register. Writing this bit to a 1 sets the mask to 1 to enable the associated error/alarm. Reading this register returns the value of the mask bit.
  [10] RM_RCVD_RAI_MSK rw — Mask for associated bit in the EE_EV1_LINK_ISM_A register. Writing this bit to a 1 sets the mask to 1 to enable the associated error/alarm. Reading this register returns the value of the mask bit.
  [9] RM_RCVD_RST_MSK rw — Mask for associated bit in the EE_EV1_LINK_ISM_A register. Writing this bit to a 1 sets the mask to 1 to enable the associated error/alarm. Reading this register returns the value of the mask bit.
  [8] RM_K30P7_DET_MSK rw — Mask for associated bit in the EE_EV1_LINK_ISM_A register. Writing this bit to a 1 sets the mask to 1 to enable the associated error/alarm. Reading this register returns the value of the mask bit.
  [7] RM_MSTR_FRAME_BNDY_OUT_OF_RANGE_MSK rw — Mask for associated bit in the EE_EV1_LINK_ISM_A register. Writing this bit to a 1 sets the mask to 1 to enable the associated error/alarm. Reading this register returns the value of the mask bit.
  [6] RM_MISSING_FRAME_INDICATOR_MSK rw — Mask for associated bit in the EE_EV1_LINK_ISM_A register. Writing this bit to a 1 sets the mask to 1 to enable the associated error/alarm. Reading this register returns the value of the mask bit.
  [5] RM_MISSING_K28P5_MSK rw — Mask for associated bit in the EE_EV1_LINK_ISM_A register. Writing this bit to a 1 sets the mask to 1 to enable the associated error/alarm. Reading this register returns the value of the mask bit.
  [4] RM_BLOCK_BNDRY_DET_MSK rw — Mask for associated bit in the EE_EV1_LINK_ISM_A register. Writing this bit to a 1 sets the mask to 1 to enable the associated error/alarm. Reading this register returns the value of the mask bit.
  [3] RM_FRAME_BNDRY_DET_MSK rw — Mask for associated bit in the EE_EV1_LINK_ISM_A register. Writing this bit to a 1 sets the mask to 1 to enable the associated error/alarm. Reading this register returns the value of the mask bit.
  [2] RM_8B10B_DECODE_ERR0R_MSK rw — Mask for associated bit in the EE_EV1_LINK_ISM_A register. Writing this bit to a 1 sets the mask to 1 to enable the associated error/alarm. Reading this register returns the value of the mask bit.
  [1] RM_LOS_DET_MSK rw — Mask for associated bit in the EE_EV1_LINK_ISM_A register. Writing this bit to a 1 sets the mask to 1 to enable the associated error/alarm. Reading this register returns the value of the mask bit.
  [0] RM_SYNC_STATUS_CHANGE_MSK rw — Mask for associated bit in the EE_EV1_LINK_ISM_A register. Writing this bit to a 1 sets the mask to 1 to enable the associated error/alarm. Reading this register returns the value of the mask bit.
{0x30024+0x800*i} EE_EV1_LINK_MSK_SET_B{i} (i=0..5) — Event 1 Link Interrupt Source Mask Set Reg B
  [20] DB_CIRSW_OUT_DMA_UFLOW_MSK rw — Mask for associated bit in the EE_EV1_LINK_ISM_A register. Writing this bit to a 1 sets the mask to 1 to enable the associated error/alarm. Reading this register returns the value of the mask bit.
  [19] DB_CIRSW_IN_DMA_UFLOW_MSK rw — Mask for associated bit in the EE_EV1_LINK_ISM_A register. Writing this bit to a 1 sets the mask to 1 to enable the associated error/alarm. Reading this register returns the value of the mask bit.
  [18] DB_CIRSW_OUT_BURST_OFLOW_MSK rw — Mask for associated bit in the EE_EV1_LINK_ISM_A register. Writing this bit to a 1 sets the mask to 1 to enable the associated error/alarm. Reading this register returns the value of the mask bit.
  [17] DB_CIRSW_OUT_DMA_OFLOW_MSK rw — Mask for associated bit in the EE_EV1_LINK_ISM_A register. Writing this bit to a 1 sets the mask to 1 to enable the associated error/alarm. Reading this register returns the value of the mask bit.
  [16] DB_CIRSW_IN_DMA_OFLOW_MSK rw — Mask for associated bit in the EE_EV1_LINK_ISM_A register. Writing this bit to a 1 sets the mask to 1 to enable the associated error/alarm. Reading this register returns the value of the mask bit.
  [13] CD_OUT_FIFO_UNF_MSK rw — Mask for associated bit in the EE_EV1_LINK_ISM_A register. Writing this bit to a 1 sets the mask to 1 to enable the associated error/alarm. Reading this register returns the value of the mask bit.
  [12] CD_OUT_FIFO_OVF_MSK rw — Mask for associated bit in the EE_EV1_LINK_ISM_A register. Writing this bit to a 1 sets the mask to 1 to enable the associated error/alarm. Reading this register returns the value of the mask bit.
  [10] AG_LINK_SUM_OVF_MSK rw — Mask for associated bit in the EE_EV1_LINK_ISM_A register. Writing this bit to a 1 sets the mask to 1 to enable the associated error/alarm. Reading this register returns the value of the mask bit.
  [9] AG_FRM_ALIGN_ERR_MSK rw — Mask for associated bit in the EE_EV1_LINK_ISM_A register. Writing this bit to a 1 sets the mask to 1 to enable the associated error/alarm. Reading this register returns the value of the mask bit.
  [8] AG_LINK_HDR_ERR_MSK rw — Mask for associated bit in the EE_EV1_LINK_ISM_A register. Writing this bit to a 1 sets the mask to 1 to enable the associated error/alarm. Reading this register returns the value of the mask bit.
  [4] TM_FIFO_UNF_MSK rw — Mask for associated bit in the EE_EV1_LINK_ISM_A register. Writing this bit to a 1 sets the mask to 1 to enable the associated error/alarm. Reading this register returns the value of the mask bit.
  [3] TM_FIFO_OVF_MSK rw — Mask for associated bit in the EE_EV1_LINK_ISM_A register. Writing this bit to a 1 sets the mask to 1 to enable the associated error/alarm. Reading this register returns the value of the mask bit.
  [2] TM_DATA_NOT_ALIGNED_MSK rw — Mask for associated bit in the EE_EV1_LINK_ISM_A register. Writing this bit to a 1 sets the mask to 1 to enable the associated error/alarm. Reading this register returns the value of the mask bit.
  [1] TM_FRAME_NOT_ALIGNED_MSK rw — Mask for associated bit in the EE_EV1_LINK_ISM_A register. Writing this bit to a 1 sets the mask to 1 to enable the associated error/alarm. Reading this register returns the value of the mask bit.
  [0] TM_SYNC_STATUS_CHANGE_MSK rw — Mask for associated bit in the EE_EV1_LINK_ISM_A register. Writing this bit to a 1 sets the mask to 1 to enable the associated error/alarm. Reading this register returns the value of the mask bit.
